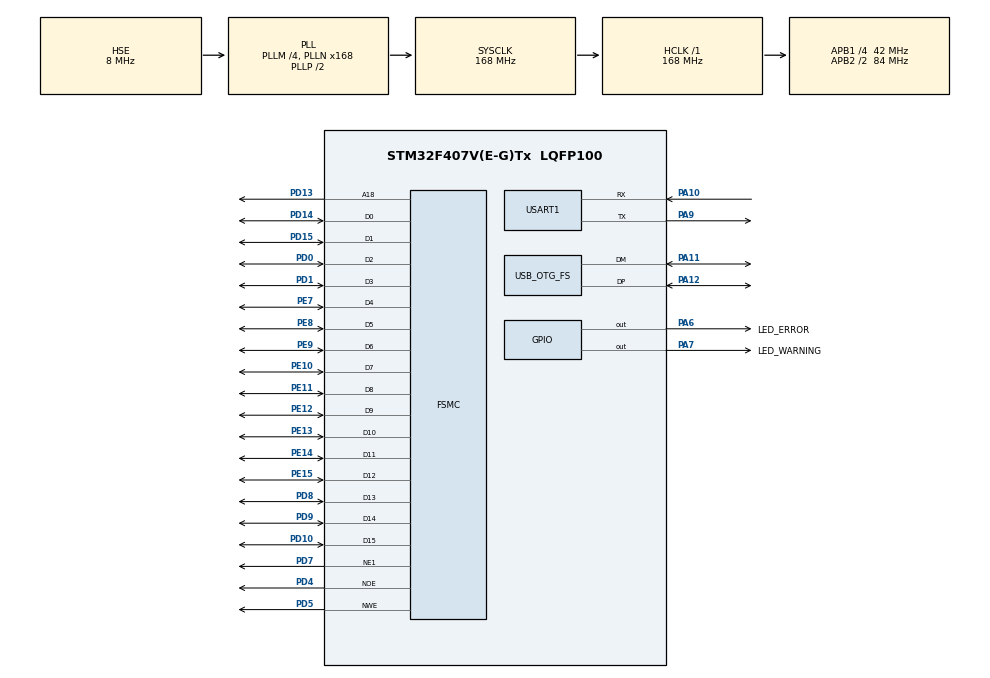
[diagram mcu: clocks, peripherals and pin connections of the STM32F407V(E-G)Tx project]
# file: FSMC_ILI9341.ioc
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FSMC.AddressSetupTime1=6
FSMC.BusTurnAroundDuration1=0
FSMC.DataSetupTime1=6
Mcu.Family=STM32F4
Mcu.Name=STM32F407V(E-G)Tx
Mcu.Package=LQFP100
NVIC.OTG_FS_IRQn=true\:0\:0\:false\:false\:true\:false\:true
NVIC.PriorityGroup=NVIC_PRIORITYGROUP_4
NVIC.USART1_IRQn=true\:0\:0\:false\:false\:true\:true\:true
PA10.Mode=Asynchronous
PA10.Signal=USART1_RX
PA11.Mode=Device_Only
PA11.Signal=USB_OTG_FS_DM
PA12.Mode=Device_Only
PA12.Signal=USB_OTG_FS_DP
PA13.Mode=Trace_Synchro_1bit_JTAG
PA13.Signal=SYS_JTMS-SWDIO
PA14.Mode=Trace_Synchro_1bit_JTAG
PA14.Signal=SYS_JTCK-SWCLK
PA15.Mode=Trace_Synchro_1bit_JTAG
PA15.Signal=SYS_JTDI
PA6.GPIO_Label=LED_ERROR
PA6.GPIO_PuPd=GPIO_PULLUP
PA6.PinState=GPIO_PIN_SET
PA6.Signal=GPIO_Output
PA7.GPIO_Label=LED_WARNING
PA7.GPIO_PuPd=GPIO_PULLUP
PA7.PinState=GPIO_PIN_SET
PA7.Signal=GPIO_Output
PA9.Mode=Asynchronous
PA9.Signal=USART1_TX
PB3.Mode=Trace_Synchro_1bit_JTAG
PB3.Signal=SYS_JTDO-SWO
PD0.Mode=16b-d1
PD0.Signal=FSMC_D2
PD1.Mode=16b-d1
PD1.Signal=FSMC_D3
PD10.Mode=16b-d1
PD10.Signal=FSMC_D15
PD13.Mode=A18_1
PD13.Signal=FSMC_A18
PD14.Mode=16b-d1
PD14.Signal=FSMC_D0
PD15.Mode=16b-d1
PD15.Signal=FSMC_D1
PD4.Mode=Lcd1
PD4.Signal=FSMC_NOE
PD5.Mode=Lcd1
PD5.Signal=FSMC_NWE
PD7.Mode=NorPsramChipSelect1_1
PD7.Signal=FSMC_NE1
PD8.Mode=16b-d1
PD8.Signal=FSMC_D13
PD9.Mode=16b-d1
PD9.Signal=FSMC_D14
PE10.Mode=16b-d1
PE10.Signal=FSMC_D7
PE11.Mode=16b-d1
PE11.Signal=FSMC_D8
PE12.Mode=16b-d1
PE12.Signal=FSMC_D9
PE13.Mode=16b-d1
PE13.Signal=FSMC_D10
PE14.Mode=16b-d1
PE14.Signal=FSMC_D11
PE15.Mode=16b-d1
PE15.Signal=FSMC_D12
PE2.Mode=Trace_Synchro_1bit_JTAG
PE2.Signal=SYS_TRACECLK
PE3.Mode=Trace_Synchro_1bit_JTAG
PE3.Signal=SYS_TRACED0
PE7.Mode=16b-d1
PE7.Signal=FSMC_D4
PE8.Mode=16b-d1
PE8.Signal=FSMC_D5
PE9.Mode=16b-d1
PE9.Signal=FSMC_D6
PH0-OSC_IN.Mode=HSE-External-Oscillator
PH0-OSC_IN.Signal=RCC_OSC_IN
PH1-OSC_OUT.Mode=HSE-External-Oscillator
PH1-OSC_OUT.Signal=RCC_OSC_OUT
ProjectManager.HeapSize=0x2000
ProjectManager.StackSize=0x4000
ProjectManager.TargetToolchain=STM32CubeIDE
RCC.48MHZClocksFreq_Value=48000000
RCC.AHBFreq_Value=168000000
RCC.APB1CLKDivider=RCC_HCLK_DIV4
RCC.APB1Freq_Value=42000000
RCC.APB1TimFreq_Value=84000000
RCC.APB2CLKDivider=RCC_HCLK_DIV2
RCC.APB2Freq_Value=84000000
RCC.APB2TimFreq_Value=168000000
RCC.CortexFreq_Value=168000000
RCC.HCLKFreq_Value=168000000
RCC.HSE_VALUE=8000000
RCC.HSI_VALUE=16000000
RCC.LSE_VALUE=32768
RCC.PLLM=4
RCC.PLLN=168
RCC.PLLQ=7
RCC.SYSCLKFreq_VALUE=168000000
RCC.SYSCLKSource=RCC_SYSCLKSOURCE_PLLCLK
RCC.VCOOutputFreq_Value=336000000
USART1.VirtualMode=VM_ASYNC
USB_DEVICE.CLASS_NAME_FS=CDC
USB_DEVICE.VirtualMode-CDC_FS=Cdc
USB_DEVICE.VirtualModeFS=Cdc_FS
USB_OTG_FS.VirtualMode=Device_Only
VP_USB_DEVICE_VS_USB_DEVICE_CDC_FS.Mode=CDC_FS
board=custom

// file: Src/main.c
/* USER CODE BEGIN Header */
/**
  ******************************************************************************
  * @file           : main.c
  * @brief          : Main program body
  ******************************************************************************
  * @attention
  *
  * <h2><center>&copy; Copyright (c) 2019 STMicroelectronics.
  * All rights reserved.</center></h2>
  *
  * This software component is licensed by ST under Ultimate Liberty license
  * SLA0044, the "License"; You may not use this file except in compliance with
  * the License. You may obtain a copy of the License at:
  *                             www.st.com/SLA0044
  *
  ******************************************************************************
  */
/* USER CODE END Header */

#include "main.h"
#include "usart.h"
#include "usb_device.h"
#include "gpio.h"
#include "fsmc.h"

void SystemClock_Config(void);
/* USER CODE BEGIN PFP */
int application(void);
/* USER CODE END PFP */

int main(void)
{

  /* MCU Configuration--------------------------------------------------------*/

  /* Reset of all peripherals, Initializes the Flash interface and the Systick. */
  HAL_Init();

  /* Configure the system clock */
  SystemClock_Config();

  /* Initialize all configured peripherals */
  MX_GPIO_Init();
  MX_FSMC_Init();
  MX_USART1_UART_Init();
  MX_USB_DEVICE_Init();
  /* USER CODE BEGIN 2 */
  return application();
  /* USER CODE END 2 */

  /* Infinite loop */
  while (1)
  {

  }
}

void SystemClock_Config(void)
{
  RCC_OscInitTypeDef RCC_OscInitStruct = {0};
  RCC_ClkInitTypeDef RCC_ClkInitStruct = {0};

  /** Configure the main internal regulator output voltage
  */
  __HAL_RCC_PWR_CLK_ENABLE();
  __HAL_PWR_VOLTAGESCALING_CONFIG(PWR_REGULATOR_VOLTAGE_SCALE1);
  /** Initializes the CPU, AHB and APB busses clocks
  */
  RCC_OscInitStruct.OscillatorType = RCC_OSCILLATORTYPE_HSE;
  RCC_OscInitStruct.HSEState = RCC_HSE_ON;
  RCC_OscInitStruct.PLL.PLLState = RCC_PLL_ON;
  RCC_OscInitStruct.PLL.PLLSource = RCC_PLLSOURCE_HSE;
  RCC_OscInitStruct.PLL.PLLM = 4;
  RCC_OscInitStruct.PLL.PLLN = 168;
  RCC_OscInitStruct.PLL.PLLP = RCC_PLLP_DIV2;
  RCC_OscInitStruct.PLL.PLLQ = 7;
  if (HAL_RCC_OscConfig(&RCC_OscInitStruct) != HAL_OK)
  {
    Error_Handler();
  }
  /** Initializes the CPU, AHB and APB busses clocks
  */
  RCC_ClkInitStruct.ClockType = RCC_CLOCKTYPE_HCLK|RCC_CLOCKTYPE_SYSCLK
                              |RCC_CLOCKTYPE_PCLK1|RCC_CLOCKTYPE_PCLK2;
  RCC_ClkInitStruct.SYSCLKSource = RCC_SYSCLKSOURCE_PLLCLK;
  RCC_ClkInitStruct.AHBCLKDivider = RCC_SYSCLK_DIV1;
  RCC_ClkInitStruct.APB1CLKDivider = RCC_HCLK_DIV4;
  RCC_ClkInitStruct.APB2CLKDivider = RCC_HCLK_DIV2;

  if (HAL_RCC_ClockConfig(&RCC_ClkInitStruct, FLASH_LATENCY_5) != HAL_OK)
  {
    Error_Handler();
  }
}

void Error_Handler(void)
{
}

/************************ (C) COPYRIGHT STMicroelectronics *****END OF FILE****/
